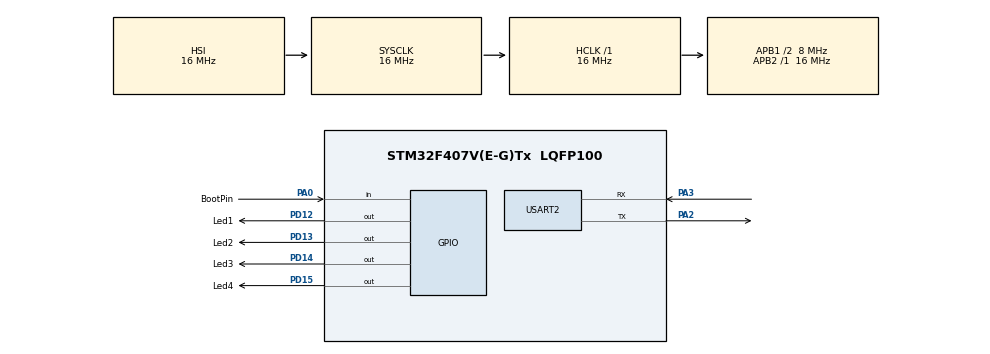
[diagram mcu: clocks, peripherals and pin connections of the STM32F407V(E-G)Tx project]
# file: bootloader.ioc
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Mcu.Family=STM32F4
Mcu.Name=STM32F407V(E-G)Tx
Mcu.Package=LQFP100
NVIC.PriorityGroup=NVIC_PRIORITYGROUP_4
PA0-WKUP.GPIO_Label=BootPin
PA0-WKUP.Signal=GPIO_Input
PA2.Mode=Asynchronous
PA2.Signal=USART2_TX
PA3.Mode=Asynchronous
PA3.Signal=USART2_RX
PD12.GPIO_Label=Led1
PD12.Signal=GPIO_Output
PD13.GPIO_Label=Led2
PD13.Signal=GPIO_Output
PD14.GPIO_Label=Led3
PD14.Signal=GPIO_Output
PD15.GPIO_Label=Led4
PD15.Signal=GPIO_Output
ProjectManager.HeapSize=0x200
ProjectManager.StackSize=0x400
ProjectManager.TargetToolchain=Makefile
RCC.48MHZClocksFreq_Value=16666666.666666666
RCC.AHBFreq_Value=16000000
RCC.APB1CLKDivider=RCC_HCLK_DIV2
RCC.APB1Freq_Value=8000000
RCC.APB1TimFreq_Value=16000000
RCC.APB2Freq_Value=16000000
RCC.APB2TimFreq_Value=16000000
RCC.CortexFreq_Value=16000000
RCC.HCLKFreq_Value=16000000
RCC.HSE_VALUE=25000000
RCC.HSI_VALUE=16000000
RCC.LSE_VALUE=32768
RCC.PLLM=12
RCC.PLLN=50
RCC.SYSCLKFreq_VALUE=16000000
RCC.VCOOutputFreq_Value=66666666.666666664
USART2.VirtualMode=VM_ASYNC
VP_CRC_VS_CRC.Mode=CRC_Activate
board=custom

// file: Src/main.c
/* USER CODE BEGIN Header */
/**
  ******************************************************************************
  * @file           : main.c
  * @brief          : Main program body
  ******************************************************************************
  * @attention
  *
  * <h2><center>&copy; Copyright (c) 2020 STMicroelectronics.
  * All rights reserved.</center></h2>
  *
  * This software component is licensed by ST under BSD 3-Clause license,
  * the "License"; You may not use this file except in compliance with the
  * License. You may obtain a copy of the License at:
  *                        opensource.org/licenses/BSD-3-Clause
  *
  ******************************************************************************
  */
/* USER CODE END Header */

#include "main.h"

/* USER CODE BEGIN Includes */

#include "../Inc/Bootloader.h"
/* USER CODE END Includes */

CRC_HandleTypeDef hcrc;
UART_HandleTypeDef huart2;

void SystemClock_Config(void);
static void MX_GPIO_Init(void);
static void MX_CRC_Init(void);
static void MX_USART2_UART_Init(void);

int main(void)
{

  /* MCU Configuration--------------------------------------------------------*/

  /* Reset of all peripherals, Initializes the Flash interface and the Systick. */
  HAL_Init();

  /* Configure the system clock */
  SystemClock_Config();

  /* Initialize all configured peripherals */
  MX_GPIO_Init();
  MX_CRC_Init();
  MX_USART2_UART_Init();
  /* USER CODE BEGIN 2 */
  if (HAL_GPIO_ReadPin(BootPin_GPIO_Port,BootPin_Pin)==GPIO_PIN_SET)
  {
    //HAL_UART_Transmit(&huart2,(uint8_t*)"Entered boot mode\r\n",19,HAL_MAX_DELAY);
    jump_to_bootloader();
  }
  else
  {
    //"HAL_UART_Transmit(&huart2,(uint8_t*)"Entered User App Mode\r\n",23,HAL_MAX_DELAY);
    jump_to_user_application();
  }

  //Never reach here
  /* USER CODE END 2 */

  /* Infinite loop */
  while (1)
  {
  }
}

void SystemClock_Config(void)
{
  RCC_OscInitTypeDef RCC_OscInitStruct = {0};
  RCC_ClkInitTypeDef RCC_ClkInitStruct = {0};

  /** Configure the main internal regulator output voltage
  */
  __HAL_RCC_PWR_CLK_ENABLE();
  __HAL_PWR_VOLTAGESCALING_CONFIG(PWR_REGULATOR_VOLTAGE_SCALE1);
  /** Initializes the CPU, AHB and APB busses clocks
  */
  RCC_OscInitStruct.OscillatorType = RCC_OSCILLATORTYPE_HSI;
  RCC_OscInitStruct.HSIState = RCC_HSI_ON;
  RCC_OscInitStruct.HSICalibrationValue = RCC_HSICALIBRATION_DEFAULT;
  RCC_OscInitStruct.PLL.PLLState = RCC_PLL_NONE;
  if (HAL_RCC_OscConfig(&RCC_OscInitStruct) != HAL_OK)
  {
    Error_Handler();
  }
  /** Initializes the CPU, AHB and APB busses clocks
  */
  RCC_ClkInitStruct.ClockType = RCC_CLOCKTYPE_HCLK|RCC_CLOCKTYPE_SYSCLK
                              |RCC_CLOCKTYPE_PCLK1|RCC_CLOCKTYPE_PCLK2;
  RCC_ClkInitStruct.SYSCLKSource = RCC_SYSCLKSOURCE_HSI;
  RCC_ClkInitStruct.AHBCLKDivider = RCC_SYSCLK_DIV1;
  RCC_ClkInitStruct.APB1CLKDivider = RCC_HCLK_DIV2;
  RCC_ClkInitStruct.APB2CLKDivider = RCC_HCLK_DIV1;

  if (HAL_RCC_ClockConfig(&RCC_ClkInitStruct, FLASH_LATENCY_0) != HAL_OK)
  {
    Error_Handler();
  }
}

static void MX_CRC_Init(void)
{

  hcrc.Instance = CRC;
  if (HAL_CRC_Init(&hcrc) != HAL_OK)
  {
    Error_Handler();
  }

}

static void MX_USART2_UART_Init(void)
{

  huart2.Instance = USART2;
  huart2.Init.BaudRate = 115200;
  huart2.Init.WordLength = UART_WORDLENGTH_8B;
  huart2.Init.StopBits = UART_STOPBITS_1;
  huart2.Init.Parity = UART_PARITY_NONE;
  huart2.Init.Mode = UART_MODE_TX_RX;
  huart2.Init.HwFlowCtl = UART_HWCONTROL_NONE;
  huart2.Init.OverSampling = UART_OVERSAMPLING_16;
  if (HAL_UART_Init(&huart2) != HAL_OK)
  {
    Error_Handler();
  }

}

static void MX_GPIO_Init(void)
{
  GPIO_InitTypeDef GPIO_InitStruct = {0};

  /* GPIO Ports Clock Enable */
  __HAL_RCC_GPIOA_CLK_ENABLE();
  __HAL_RCC_GPIOD_CLK_ENABLE();

  /*Configure GPIO pin Output Level */
  HAL_GPIO_WritePin(GPIOD, Led1_Pin|Led2_Pin|Led3_Pin|Led4_Pin, GPIO_PIN_RESET);

  /*Configure GPIO pin : BootPin_Pin */
  GPIO_InitStruct.Pin = BootPin_Pin;
  GPIO_InitStruct.Mode = GPIO_MODE_INPUT;
  GPIO_InitStruct.Pull = GPIO_NOPULL;
  HAL_GPIO_Init(BootPin_GPIO_Port, &GPIO_InitStruct);

  /*Configure GPIO pins : Led1_Pin Led2_Pin Led3_Pin Led4_Pin */
  GPIO_InitStruct.Pin = Led1_Pin|Led2_Pin|Led3_Pin|Led4_Pin;
  GPIO_InitStruct.Mode = GPIO_MODE_OUTPUT_PP;
  GPIO_InitStruct.Pull = GPIO_NOPULL;
  GPIO_InitStruct.Speed = GPIO_SPEED_FREQ_LOW;
  HAL_GPIO_Init(GPIOD, &GPIO_InitStruct);

}

void Error_Handler(void)
{
}

/************************ (C) COPYRIGHT STMicroelectronics *****END OF FILE****/
